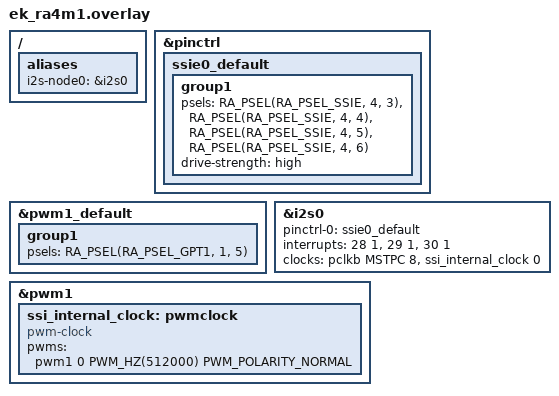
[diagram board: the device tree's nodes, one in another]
/*
 * Copyright (c) 2026 Renesas Electronics Corporation
 *
 * SPDX-License-Identifier: Apache-2.0
 */

#include <zephyr/dt-bindings/pwm/pwm.h>

/*
 * Loopback wiring on i2s0:
 *   P405 (SSI_TX) <-> P406 (SSI_RX)
 */

/ {
	aliases {
		i2s-node0 = &i2s0;
	};
};

&pinctrl {
	ssie0_default: ssie0_default {
		group1 {
			/* SSI_BCK SSI_LRCK SSI_TX SSI_RX */
			psels = <RA_PSEL(RA_PSEL_SSIE, 4, 3)>,
				<RA_PSEL(RA_PSEL_SSIE, 4, 4)>,
				<RA_PSEL(RA_PSEL_SSIE, 4, 5)>,
				<RA_PSEL(RA_PSEL_SSIE, 4, 6)>;
			drive-strength = "high";
		};
	};
};

/* P405 and P406 carry SSIE data, keep GTIOC1A on P105 */
&pwm1_default {
	group1 {
		psels = <RA_PSEL(RA_PSEL_GPT1, 1, 5)>;
	};
};

&i2s0 {
	pinctrl-0 = <&ssie0_default>;
	pinctrl-names = "default";
	interrupts = <28 1>, <29 1>, <30 1>;
	interrupt-names = "ssi_txi", "ssi_rxi", "ssi_if";
	clocks = <&pclkb MSTPC 8>, <&ssi_internal_clock 0>;
	clock-names = "pclk", "audio-clock";
	status = "okay";
};

/* GTIOC1A is the internal audio clock source of SSIE on RA4M1 */
&pwm1 {
	ssi_internal_clock: pwmclock {
		compatible = "pwm-clock";
		#clock-cells = <1>;
		pwms = <&pwm1 0 PWM_HZ(512000) PWM_POLARITY_NORMAL>;
		status = "okay";
	};
};
